# CTRL_MMR0 register map
Vendor: Texas Instruments
Registers are 32-bit, access per field, reset 0x0 unless marked. A register's access mark holds for its fields unless they carry their own. Offsets are as the file gives them; [hi:lo] are bit positions; {n}, {i} and the like mark numbered series; 'fields as' and 'values as' point back to an identical list.

## CTRL_MMR0 (part 2 of 2)
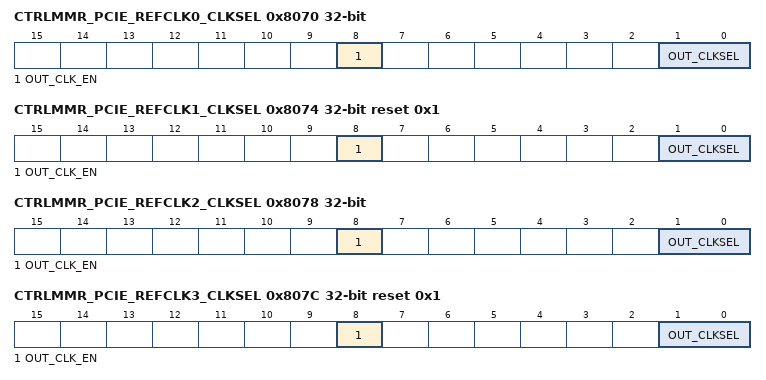
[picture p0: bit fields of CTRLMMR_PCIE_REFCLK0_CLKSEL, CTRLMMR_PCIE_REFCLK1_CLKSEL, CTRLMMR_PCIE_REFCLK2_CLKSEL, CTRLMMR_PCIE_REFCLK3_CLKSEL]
0x8070 CTRLMMR_PCIE_REFCLK0_CLKSEL — Selects the ACSPCIE clock source for the PCIE_REFCLK0 P/N output pins PCIE_REFCLK[1:0] P/N are driven by ACSPCIE0 PAD[1:0] and PCIE_REFCLK[3:2] P/N are driven by ACSPCIE1 PAD[1:0].
  [8] OUT_CLK_EN rw — Enables the output of the ACSPCIE buffer to drive the PCIE0 REFCLK P/N pins
  [1:0] OUT_CLKSEL rw — Selects the PCIE0 REFCLK output clock source. 0h - SERDES0_REF_DER_OUT_CLK 1h - SERDES1_REF_DER_OUT_CLK 2h - SERDES0_REFCLK1_OUT 3h - SERDES1_REFCLK1_OUT
0x8074 CTRLMMR_PCIE_REFCLK1_CLKSEL reset 0x1 — Selects the ACSPCIE clock source for the PCIE_REFCLK1 P/N output pins PCIE_REFCLK[1:0] P/N are driven by ACSPCIE0 PAD[1:0] and PCIE_REFCLK[3:2] P/N are driven by ACSPCIE1 PAD[1:0].
  [8] OUT_CLK_EN rw — Enables the output of the ACSPCIE buffer to drive the PCIE1 REFCLK P/N pins
  [1:0] OUT_CLKSEL rw — Selects the PCIE1 REFCLK output clock source. 0h - SERDES0_REF_DER_OUT_CLK 1h - SERDES1_REF_DER_OUT_CLK 2h - SERDES0_REFCLK1_OUT 3h - SERDES1_REFCLK1_OUT
0x8078 CTRLMMR_PCIE_REFCLK2_CLKSEL — Selects the ACSPCIE clock source for the PCIE_REFCLK2 P/N output pins PCIE_REFCLK[1:0] P/N are driven by ACSPCIE0 PAD[1:0] and PCIE_REFCLK[3:2] P/N are driven by ACSPCIE1 PAD[1:0].
  [8] OUT_CLK_EN rw — Enables the output of the ACSPCIE buffer to drive the PCIE2 REFCLK P/N pins
  [1:0] OUT_CLKSEL rw — Selects the PCIE2 REFCLK output clock source. 0h - SERDES2_REF_DER_OUT_CLK 1h - SERDES3_REF_DER_OUT_CLK 2h - SERDES2_REFCLK1_OUT 3h - SERDES3_REFCLK1_OUT
0x807C CTRLMMR_PCIE_REFCLK3_CLKSEL reset 0x1 — Selects the ACSPCIE clock source for the PCIE_REFCLK3 P/N output pins PCIE_REFCLK[1:0] P/N are driven by ACSPCIE0 PAD[1:0] and PCIE_REFCLK[3:2] P/N are driven by ACSPCIE1 PAD[1:0].
  [8] OUT_CLK_EN rw — Enables the output of the ACSPCIE buffer to drive the PCIE3 REFCLK P/N pins
  [1:0] OUT_CLKSEL rw — Selects the PCIE3 REFCLK output clock source. 0h - SERDES2_REF_DER_OUT_CLK 1h - SERDES3_REF_DER_OUT_CLK 2h - SERDES2_REFCLK1_OUT 3h - SERDES3_REFCLK1_OUT
{0x8080+4i} CTRLMMR_PCIE{i}_CLKSEL (i=0..3) — Selects PCIe{i} functional clock sources.
  [3:0] CPTS_CLKSEL rw — Selects the clock source for the PCIE{i} Common Platform Time Stamp module 0h - MAIN_PLL3_HSDIV1_CLKOUT 1h - MAIN_PLL0_HSDIV6_CLKOUT 2h - MCU_CPTS_REF_CLK (pin) 3h - CPTS_RFT_CLK (pin) 4h - MCU_EXT_REFCLK0 (pin) 5h - EXT_REFCLK1 (pin) 6h - SERDES0_IP2_LN0_TXMCLK 7h - SERDES0_IP2_LN1_TXMCLK 8h - SERDES1_IP2_LN0_TXMCLK 9h - SERDES1_IP2_LN1_TXMCLK Ah - SERDES2_IP2_LN0_TXMCLK Bh - SERDES2_IP2_LN1_TXMCLK Ch - SERDES3_IP2_LN0_TXMCLK Dh - SERDES3_IP2_LN1_TXMCLK Eh - MCU_PLL2_HSDIV1_CLKOUT Fh - MAIN_SYSCLK0
0x8090 CTRLMMR_CPSW_CLKSEL — Selects the 9X CP Switch clock sources.
  [3:0] CPTS_CLKSEL rw — Selects the clock source for the CPSW9x Ethernet switch Common Platform Time Stamp module 0h - MAIN_PLL3_HSDIV1_CLKOUT 1h - MAIN_PLL0_HSDIV6_CLKOUT 2h - MCU_CPTS_REF_CLK (pin) 3h - CPTS_RFT_CLK (pin) 4h - MCU_EXT_REFCLK0 (pin) 5h - EXT_REFCLK1 (pin) 6h - SERDES0_IP2_LN0_TXMCLK 7h - SERDES0_IP2_LN1_TXMCLK 8h - SERDES1_IP2_LN0_TXMCLK 9h - SERDES1_IP2_LN1_TXMCLK Ah - SERDES2_IP2_LN0_TXMCLK Bh - SERDES2_IP2_LN1_TXMCLK Ch - SERDES3_IP2_LN0_TXMCLK Dh - SERDES3_IP2_LN1_TXMCLK Eh - MCU_PLL2_HSDIV1_CLKOUT Fh - MAIN_SYSCLK0
0x8098 CTRLMMR_NAVSS_CLKSEL — Selects the clock source for the Nav Subsystem.
  [3:0] CPTS_CLKSEL rw — Selects the clock source for the SoC] Common Platform Time Stamp module located within the Nav Subsystem 0h - MAIN_PLL3_HSDIV1_CLKOUT 1h - MAIN_PLL0_HSDIV6_CLKOUT 2h - MCU_CPTS_REF_CLK (pin) 3h - CPTS_RFT_CLK (pin) 4h - MCU_EXT_REFCLK0 (pin) 5h - EXT_REFCLK1 (pin) 6h - SERDES0_IP2_LN0_TXMCLK 7h - SERDES0_IP2_LN1_TXMCLK 8h - SERDES1_IP2_LN0_TXMCLK 9h - SERDES1_IP2_LN1_TXMCLK Ah - SERDES2_IP2_LN0_TXMCLK Bh - SERDES2_IP2_LN1_TXMCLK Ch - SERDES3_IP2_LN0_TXMCLK Dh - SERDES3_IP2_LN1_TXMCLK Eh - MCU_PLL2_HSDIV1_CLKOUT Fh - MAIN_SYSCLK0
0x80B0 CTRLMMR_EMMC0_CLKSEL — Selects the functional clock source for 8-bit eMMC0.
  [1:0] CLK_SEL rw — eMMC XIN_CLK selection
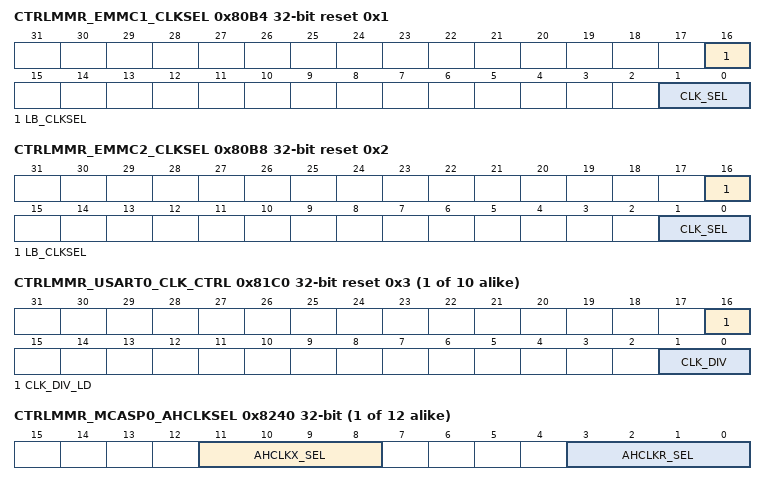
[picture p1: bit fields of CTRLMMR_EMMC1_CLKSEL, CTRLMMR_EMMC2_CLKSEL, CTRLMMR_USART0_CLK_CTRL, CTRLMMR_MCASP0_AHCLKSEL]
0x80B4 CTRLMMR_EMMC1_CLKSEL reset 0x1 — Selects the functional clock source for 4-bit eMMC1.
  [16] LB_CLKSEL rw — eMMC Loopback clock selection
  [1:0] CLK_SEL rw — eMMC XIN_CLK selection
0x80B8 CTRLMMR_EMMC2_CLKSEL reset 0x2 — Selects the functional clock source for 4-bit eMMC2.
  fields as CTRLMMR_EMMC1_CLKSEL
0x80C0 CTRLMMR_UFS0_CLKSEL — Selects the clocks for Universal Flash Storage 0 interface.
  [1:0] MCLK_SEL rw — Selects the MPHY clock source
0x80D0 CTRLMMR_GPMC_CLKSEL — Selects the bus and functional clock source for the GPMC module. This allows the GPMC to run asynchronously to the bus fabric in order to optimize parallel port performance.
  [1:0] CLK_SEL rw — Selects the GPMC clock source
0x80E0 CTRLMMR_USB0_CLKSEL — Selects the functional clock sources for USB0.
  [0] REFCLK_SEL rw — Selects the clock source for the USB0 ref_clk.
0x80E4 CTRLMMR_USB1_CLKSEL — Selects the functional clock sources for USB1.
  [0] REFCLK_SEL rw — Selects the clock source for the USB1 ref_clk.
{0x8100+4i} CTRLMMR_TIMER{i}_CLKSEL (i=0..19) — Timer{i} functional clock selection control.
  [3:0] CLK_SEL rw — Timer functional clock input select mux control 0h - WKUP_HFOSC0_CLKOUT 1h - HFOSC1_CLKOUT 2h - MAIN_PLL0_HSDIV1_CLKOUT 3h - CLK_12M_RC 4h - MAIN_PLL3_HSDIV3_CLKOUT 5h - MCU_EXT_REFCLK0 (pin) 6h - EXT_REFCLK1 (pin) 7h - LPXOSC_CLKOUT 8h - CPTS_RFT_CLK (pin) 9h - MAIN_PLL1_HSDIV3_CLKOUT Ah - MAIN_PLL2_HSDIV6_CLKOUT Bh - MAIN_PLL4_HSDIV2_CLKOUT Ch - CPTS_GENF2 Dh - CPTS_GENF3 Eh - CPSW9G_CPTS_GENF0 Fh - MAIN_PLL15_HSDIV2_CLKOUT
{0x8190+4i} CTRLMMR_SPI{i}_CLKSEL (i=0..3) — SPI{i} clock control.
  [16] MSTR_LB_CLKSEL rw — Master mode receive capture clock loopback selection
{0x8190+4i} CTRLMMR_SPI{i}_CLKSEL (i=5..7) — SPI{i} clock control.
  fields as CTRLMMR_SPI0_CLKSEL
{0x81C0+4i} CTRLMMR_USART{i}_CLK_CTRL reset 0x3 (i=0..9) — Selects the clock divider of the USART{i} functional clock.
  [16] CLK_DIV_LD rw — Load the output divider value
  [1:0] CLK_DIV rw — Selects the clock divider value. Supports divide values of 1 to 4 Default is /4. To load the new divider value the clk_div_ld bit must be cleared and then set to 1. 0h - Divide by 1 1h - Divide by 2 2h - Divide by 3 3h - Divide by 4
{0x8200+4i} CTRLMMR_MCASP{i}_CLKSEL (i=0..11) — Selects the functional clock source for McASP{i}.
  [2:0] AUXCLK_SEL rw — Selects the McASP{i} auxclk clock source 0h - MAIN_PLL4_HSDIV0_CLKOUT 1h - MAIN_PLL2_HSDIV2_CLKOUT 2h - MAIN_PLL15_HSDIV0_CLKOUT 3h - '0' 4h - ATCLK0 5h - ATCLK1 6h - ATCLK2 7h - ATCLK3
{0x8240+4i} CTRLMMR_MCASP{i}_AHCLKSEL (i=0..11) — Selects the AHCLKX and AHCLKR clock source for McASP{i}.
  [11:8] AHCLKX_SEL rw — Selects the AHCLKX input source for McASP{i}. Not shown values are reserved. 0h - HFOSC1_CLKOUT 1h - WKUP_HFOSC0_CLKOUT 2h - AUDIO_EXT_REFCLK0_IN 3h - AUDIO_EXT_REFCLK1_IN 4h - AUDIO_EXT_REFCLK2_IN 5h - AUDIO_EXT_REFCLK3_IN 6h - MLB_IO_CLK 7h - MLBP_IO_CLK / 2 8h - ATCLK0 9h - ATCLK1 Ah - ATCLK2 Bh - ATCLK3
  [3:0] AHCLKR_SEL rw — Selects the AHCLKR input source for McASP{i} 0h - HFOSC1_CLKOUT 1h - WKUP_HFOSC0_CLKOUT 2h - AUDIO_EXT_REFCLK0_IN 3h - AUDIO_EXT_REFCLK1_IN 4h - AUDIO_EXT_REFCLK2_IN 5h - AUDIO_EXT_REFCLK3_IN 6h - MLB_IO_CLK 7h - MLBP_IO_CLK / 2 8h - ATCLK0 9h - ATCLK1 Ah - ATCLK2 Bh - ATCLK3 Ch - '0' Dh - '0' Eh - '0' Fh - '0'
{0x8280+4i} CTRLMMR_ASRC_RXSYNC{i}_SEL (i=0..3) — Selects the source signal for the ASRC RXSYNC{i} frame sync input.
  [5:0] SYNC_SEL rw — RXSYNC source signal. Not shown values are reserved. 0h - McASP0 AFSR Pin Input 1h - McASP1 AFSR Pin Input 2h - McASP2 AFSR Pin Input 3h - McASP3 AFSR Pin Input 4h - McASP4 AFSR Pin Input 5h - McASP5 AFSR Pin Input 6h - McASP6 AFSR Pin Input 7h - McASP7 AFSR Pin Input 8h - McASP8 AFSR Pin Input 9h - McASP9 AFSR Pin Input Ah - McASP10 AFSR Pin Input Bh - McASP11 AFSR Pin Input Ch - McASP0 AFSX Pin Input Dh - McASP1 AFSX Pin Input Eh - McASP2 AFSX Pin Input Fh - McASP3 AFSX Pin Input 10h - McASP4 AFSX Pin Input 11h - McASP5 AFSX Pin Input 12h - McASP6 AFSX Pin Input 13h - McASP7 AFSX Pin Input 14h - McASP8 AFSX Pin Input 15h - McASP9 AFSX Pin Input 16h - McASP10 AFSX Pin Input 17h - McASP11 AFSX Pin Input 18h - AUDIO_EXT_REFCLK0 Pin input 19h - AUDIO_EXT_REFCLK1 Pin input 1Ah - AUDIO_EXT_REFCLK2 Pin input 1Bh - AUDIO_EXT_REFCLK3 Pin input 1Ch - MLB_IO_CLK 1Dh - MLBP_IO_CLK /2 1Eh - MAIN_PLL4_HSDIV3_CLKOUT 1Fh - MAIN_PLL15_HSDIV3_CLKOUT 20h - ADC0_CLK 21h - ADC1_CLK 22h - MCU_EXT_REFCLK0 Pin 23h - EXT_REFCLK1 Pin
{0x8290+4i} CTRLMMR_ASRC_TXSYNC{i}_SEL (i=0..3) — Selects the source signal for the ASRC TXSYNC{i} frame sync input.
  [5:0] SYNC_SEL rw — TXSYNC source signal. Not shown values are reserved. 0h - McASP0 AFSX Pin Input 1h - McASP1 AFSX Pin Input 2h - McASP2 AFSX Pin Input 3h - McASP3 AFSX Pin Input 4h - McASP4 AFSX Pin Input 5h - McASP5 AFSX Pin Input 6h - McASP6 AFSX Pin Input 7h - McASP7 AFSX Pin Input 8h - McASP8 AFSX Pin Input 9h - McASP9 AFSX Pin Input Ah - McASP10 AFSX Pin Input Bh - McASP11 AFSX Pin Input Ch - McASP0 AFSX Pin Input Dh - McASP1 AFSX Pin Input Eh - McASP2 AFSX Pin Input Fh - McASP3 AFSX Pin Input 10h - McASP4 AFSX Pin Input 11h - McASP5 AFSX Pin Input 12h - McASP6 AFSX Pin Input 13h - McASP7 AFSX Pin Input 14h - McASP8 AFSX Pin Input 15h - McASP9 AFSX Pin Input 16h - McASP10 AFSX Pin Input 17h - McASP11 AFSX Pin Input 18h - AUDIO_EXT_REFCLK0 Pin input 19h - AUDIO_EXT_REFCLK1 Pin input 1Ah - AUDIO_EXT_REFCLK2 Pin input 1Bh - AUDIO_EXT_REFCLK3 Pin input 1Ch - MLB_IO_CLK 1Dh - MLBP_IO_CLK /2 1Eh - MAIN_PLL4_HSDIV3_CLKOUT 1Fh - MAIN_PLL15_HSDIV3_CLKOUT 20h - ADC0_CLK 21h - ADC1_CLK 22h - MCU_EXT_REFCLK0 Pin 23h - EXT_REFCLK1 Pin
{0x82A0+4i} CTRLMMR_ATL_BWS{i}_SEL (i=0..3) — Selects the source of ATL Baseband Word Select {i}.
  [4:0] WD_SEL rw — BWS source signal. Not shown values are reserved. 0h - McASP0 AFSR Pin Input 1h - McASP1 AFSR Pin Input 2h - McASP2 AFSR Pin Input 3h - McASP3 AFSR Pin Input 4h - McASP4 AFSR Pin Input 5h - McASP5 AFSR Pin Input 6h - McASP6 AFSR Pin Input 7h - McASP7 AFSR Pin Input 8h - McASP8 AFSR Pin Input 9h - McASP9 AFSR Pin Input Ah - McASP10 AFSR Pin Input Bh - McASP11 AFSR Pin Input Ch - McASP0 AFSX Pin Input Dh - McASP1 AFSX Pin Input Eh - McASP2 AFSX Pin Input Fh - McASP3 AFSX Pin Input 10h - McASP4 AFSX Pin Input 11h - McASP5 AFSX Pin Input 12h - McASP6 AFSX Pin Input 13h - McASP7 AFSX Pin Input 14h - McASP8 AFSX Pin Input 15h - McASP9 AFSX Pin Input 16h - McASP10 AFSX Pin Input 17h - McASP11 AFSX Pin Input 18h - AUDIO_EXT_REFCLK0 Pin input 19h - AUDIO_EXT_REFCLK1 Pin input 1Ah - AUDIO_EXT_REFCLK2 Pin input 1Bh - AUDIO_EXT_REFCLK3 Pin input
{0x82B0+4i} CTRLMMR_ATL_AWS{i}_SEL (i=0..3) — Selects the source of ATL Audio Word Select {i}.
  [4:0] WD_SEL rw — AWS source signal. Not shown values are reserved. 0h - McASP0 AFSX Pin Input 1h - McASP1 AFSX Pin Input 2h - McASP2 AFSX Pin Input 3h - McASP3 AFSX Pin Input 4h - McASP4 AFSX Pin Input 5h - McASP5 AFSX Pin Input 6h - McASP6 AFSX Pin Input 7h - McASP7 AFSX Pin Input 8h - McASP8 AFSX Pin Input 9h - McASP9 AFSX Pin Input Ah - McASP10 AFSX Pin Input Bh - McASP11 AFSX Pin Input Ch - McASP0 AFSX Pin Input Dh - McASP1 AFSX Pin Input Eh - McASP2 AFSX Pin Input Fh - McASP3 AFSX Pin Input 10h - McASP4 AFSX Pin Input 11h - McASP5 AFSX Pin Input 12h - McASP6 AFSX Pin Input 13h - McASP7 AFSX Pin Input 14h - McASP8 AFSX Pin Input 15h - McASP9 AFSX Pin Input 16h - McASP10 AFSX Pin Input 17h - McASP11 AFSX Pin Input 18h - AUDIO_EXT_REFCLK0 Pin input 19h - AUDIO_EXT_REFCLK1 Pin input 1Ah - AUDIO_EXT_REFCLK2 Pin input 1Bh - AUDIO_EXT_REFCLK3 Pin input 1Ch - MLB_IO_CLK 1Dh - MLBP_IO_CLK /2
0x82C0 CTRLMMR_ATL_CLKSEL — Selects the source of the ATL PCLK.
  [3:0] PCLK_SEL rw — Selects the PCLK clock source 0h - MAIN_PLL4_HSDIV1_CLKOUT 1h - MAIN_PLL2_HSDIV2_CLKOUT 2h - MAIN_PLL15_HSDIV1_CLKOUT 3h - '0' 4h - MAIN_PLL0_HSDIV7_CLKOUT 5h - MCU_EXT_REFCLK0 (pin) 6h - EXT_REFCLK1 (pin) 7h - '0'
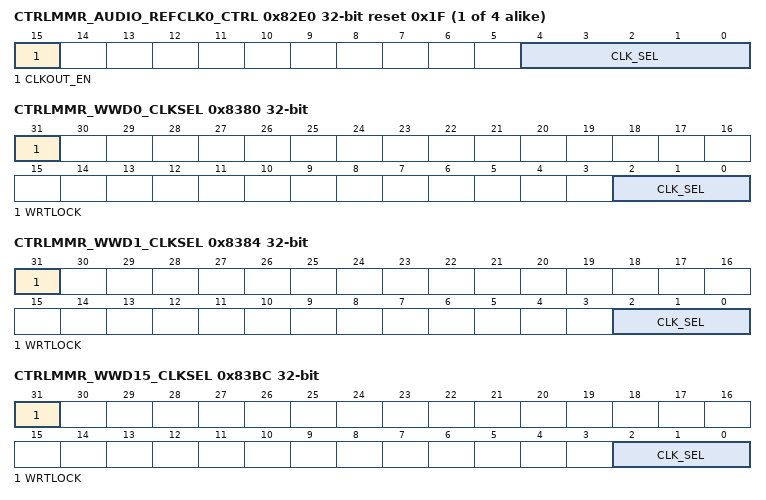
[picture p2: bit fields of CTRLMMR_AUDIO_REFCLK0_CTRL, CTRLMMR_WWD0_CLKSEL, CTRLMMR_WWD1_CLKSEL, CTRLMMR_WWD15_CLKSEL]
{0x82E0+4i} CTRLMMR_AUDIO_REFCLK{i}_CTRL reset 0x1F (i=0..3) — Selects the clock source for the AUDIO_EXT_REFCLK{i} output.
  [15] CLKOUT_EN rw — AUDIO_REFCLK {i} output enable
  [4:0] CLK_SEL rw — Clock source 0h - MCASP0 AHCLKR Output 1h - MCASP1 AHCLKR Output 2h - MCASP2 AHCLKR Output 3h - MCASP3 AHCLKR Output 4h - MCASP4 AHCLKR Output 5h - MCASP5 AHCLKR Output 6h - MCASP6 AHCLKR Output 7h - MCASP7 AHCLKR Output 8h - MCASP8 AHCLKR Output 9h - MCASP9 AHCLKR Output Ah - MCASP10 AHCLKR Output Bh - MCASP11 AHCLKR Output Ch - MCASP0 AHCLKX Output Dh - MCASP1 AHCLKX Output Eh - MCASP2 AHCLKX Output Fh - MCASP3 AHCLKX Output 10h - MCASP4 AHCLKX Output 11h - MCASP5 AHCLKX Output 12h - MCASP6 AHCLKX Output 13h - MCASP7 AHCLKX Output 14h - MCASP8 AHCLKX Output 15h - MCASP9 AHCLKX Output 16h - MCASP10 AHCLKX Output 17h - MCASP11 AHCLKX Output 18h - ATCLK0 19h - ATCLK1 1Ah - ATCLK2 1Bh - ATCLK3 1Ch - MAIN_PLL4_HSDIV2_CLKOUT 1Dh - MAIN_PLL15_HSDIV2_CLKOUT 1Eh - '0' 1Fh - '0'
0x8300 CTRLMMR_DPI0_CLK_CTRL — Selects the clock source for the DPI0 video output.
  [0] EXT_CLKSEL rw — Selects whether to use DSS PLL3 or an external pin as a DPI clock source.
0x8304 CTRLMMR_DPI1_CLK_CTRL — Selects the clock source for the DPI1 video output.
  [0] EXT_CLKSEL rw — Selects whether to use DSS PLL7 or an external pin as a DPI clock source.
0x8310 CTRLMMR_DPHY0_CLKSEL — Selects the clock source for the DSI0 transmit PHY.
  [1:0] REF_CLK_SEL rw — DPHY reference clock source
0x8324 CTRLMMR_DSS_DISPC0_CLKSEL1 — Selects the clock source for DPI Lane 1 of Display Controller Instance 0.
  [1:0] DPI1_PCLK rw — DPI lane 1 pixel clock source 0h - MAIN_PLL17_HSDIV0_CLKOUT 1h - MAIN_PLL19_HSDIV0_CLKOUT_EXTPCLKIN 2h - MAIN_PLL23_HSDIV0_CLKOUT_EXTPCLKIN 3h - MAIN_PLL16_HSDIV1_CLKOUT
0x8328 CTRLMMR_DSS_DISPC0_CLKSEL2 — Selects the clock source for DPI Lane 2 of Display Controller Instance 0.
  [0] DPI2_PCLK rw — DPI lane 2 pixel clock source 0h - MAIN_PLL16_HSDIV0_CLKOUT 1h - MAIN_PLL18_HSDIV0_CLKOUT
0x832C CTRLMMR_DSS_DISPC0_CLKSEL3 — Selects the clock source for DPI Lane 3 of Display Controller Instance 0 Can also override the DPI Lane 0 and DPI Lane 2 clock source for certain values.
  [2:0] DPI3_PCLK rw — DPI lane 3 pixel clock source 0h - MAIN_PLL16_HSDIV1_CLKOUT 1h - MAIN_PLL17_HSDIV1_CLKOUT 2h - MAIN_PLL18_HSDIV1_CLKOUT 3h - MAIN_PLL19_HSDIV0_CLKOUT_EXTPCLKIN 4h - MAIN_PLL23_HSDIV0_CLKOUT_EXTPCLKIN 5h - MAIN_PLL23_HSDIV0_CLKOUT_EXTPCLKIN and dpi0_pclk = dpi1_pclk 6h - MAIN_PLL23_HSDIV0_CLKOUT_EXTPCLKIN and dpi2_pclk = MAIN_PLL19_HSDIV0_CLKOUT_EXTPCLKIN 7h - MAIN_PLL23_HSDIV0_CLKOUT_EXTPCLKIN and dpi0_pclk = dpi1_pclk and dpi2_pclk = MAIN_PLL19_HSDIV0_CLKOUT_EXTPCLKIN
0x8340 CTRLMMR_EDP_PHY0_CLKSEL — Selects the Phy core clock for Embedded Display Port Phy0.
  [1:0] CLK_SEL rw — EDP PHY CORE_REFCLK clock source
0x8350 CTRLMMR_EDP0_CLK_CTRL — Controls clock operation for Embedded Display Port 0.
  [8] DSI_CLK_DYN_SWTCH_DIS rw — EDP0 DSI clock dynamic switch disable.
0x8380 CTRLMMR_WWD0_CLKSEL — ARM MPU Core 0 Windowed watchdog timer functional clock selection control.
  [31] WRTLOCK rw — When set, locks
  [2:0] CLK_SEL rw — Windowed watchdog timer functional clock input select mux control 0h - WKUP_HFOSC0_CLKOUT 1h - LPXOSC_CLKOUT 2h - CLK_12M_RC 3h - CLK_32K 4h - HFOSC1_CLKOUT 5h - reserved (HFOSC1_CLKOUT) 6h - reserved (HFOSC1_CLKOUT) 7h - reserved (HFOSC1_CLKOUT)
0x8384 CTRLMMR_WWD1_CLKSEL — ARM MPU Core 1 Windowed watchdog timer functional clock selection control.
  fields as CTRLMMR_WWD0_CLKSEL
0x83BC CTRLMMR_WWD15_CLKSEL — GPU Windowed watchdog timer functional clock selection control.
  fields as CTRLMMR_WWD0_CLKSEL
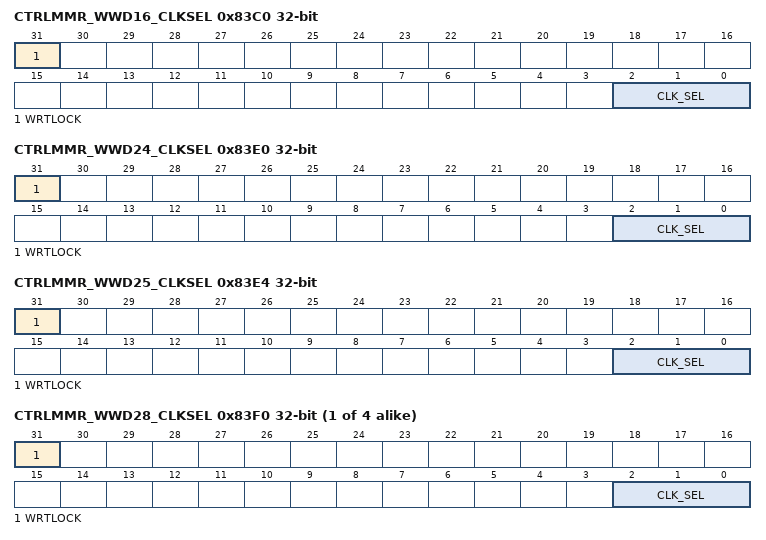
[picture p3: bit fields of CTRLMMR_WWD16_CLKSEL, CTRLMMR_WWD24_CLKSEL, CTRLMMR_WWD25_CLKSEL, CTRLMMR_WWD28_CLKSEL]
0x83C0 CTRLMMR_WWD16_CLKSEL — C71x Core 0 Windowed watchdog timer functional clock selection control.
  fields as CTRLMMR_WWD0_CLKSEL
0x83E0 CTRLMMR_WWD24_CLKSEL — C66x Core 0 Windowed watchdog timer functional clock selection control.
  fields as CTRLMMR_WWD0_CLKSEL
0x83E4 CTRLMMR_WWD25_CLKSEL — C66x Core 1 Windowed watchdog timer functional clock selection control.
  fields as CTRLMMR_WWD0_CLKSEL
{0x8380+4i} CTRLMMR_WWD{i}_CLKSEL (i=28..31) — Main R5 Core {i-28} Windowed watchdog timer functional clock selection control.
  fields as CTRLMMR_WWD0_CLKSEL
{0x8400+0x10*i} CTRLMMR_SERDES{i}_CLKSEL (i=0..3) — Selects the clock source for Lane 0 when configured as 2 single lane PHYs and Lane 0-1 when configured as a dual lane PHY.
  [1:0] CORE_REFCLK_SEL rw — Selects the source for the core_refclk input 0h - WKUP_HFOSC0_CLKOUT 1h - HFOSC1_CLKOUT 2h - MAIN_PLL3_HSDIV4_CLKOUT 3h - MAIN_PLL2_HSDIV4_CLKOUT
{0x8404+0x10*i} CTRLMMR_SERDES{i}_CLK1SEL (i=0..3) — Selects the clock source for Lane1 when configured as 2 single lane PHYs.
  [1:0] CORE_REFCLK1_SEL rw — Selects the source for the core_refclk1 input 0h - WKUP_HFOSC0_CLKOUT 1h - HFOSC1_CLKOUT 2h - MAIN_PLL3_HSDIV4_CLKOUT 3h - MAIN_PLL2_HSDIV4_CLKOUT
{0x8480+4i} CTRLMMR_MCAN{i}_CLKSEL (i=0..13) — Controls the functional clock source MCAN{i}.
  [1:0] CLK_SEL rw — MAIN MCAN_CLK selection
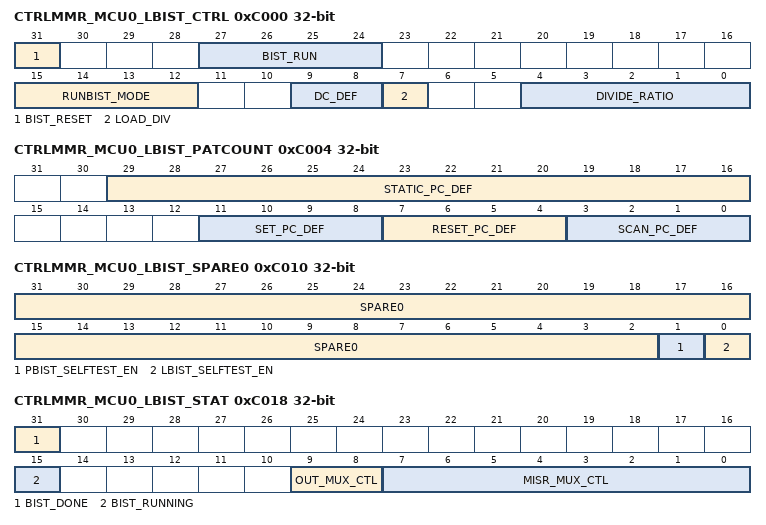
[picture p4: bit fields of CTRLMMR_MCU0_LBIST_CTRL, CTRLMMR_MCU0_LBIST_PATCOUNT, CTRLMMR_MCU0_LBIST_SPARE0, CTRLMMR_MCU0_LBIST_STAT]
0xC000 CTRLMMR_MCU0_LBIST_CTRL — Configures and enables LBIST operation.
  [31] BIST_RESET rw — Reset LBIST macro
  [27:24] BIST_RUN rw — Starts LBIST if all bits are 1
  [15:12] RUNBIST_MODE rw — Runbist mode enable if all bits are 1
  [9:8] DC_DEF rw — Clock delay after scan_enable switching
  [7] LOAD_DIV rw — Loads LBIST clock divide ratio on transition from 0 to 1
  [4:0] DIVIDE_RATIO rw — LBIST clock divide ratio
0xC004 CTRLMMR_MCU0_LBIST_PATCOUNT — Specifies the number of LBIST patterns to run.
  [29:16] STATIC_PC_DEF rw — Number of stuck-at patterns to run
  [11:8] SET_PC_DEF rw — Number of set patterns to run
  [7:4] RESET_PC_DEF rw — Number of reset patterns to run
  [3:0] SCAN_PC_DEF rw — Number of chain test patterns to run
0xC008 CTRLMMR_MCU0_LBIST_SEED0 rw — Specifies the 32 LSBs of the PRPG seed.
  [31:0] PRPG_DEF — Initial seed for PRPG (bits 31:0)
0xC00C CTRLMMR_MCU0_LBIST_SEED1 — Specifies the 21 MSBs of the PRPG seed.
  [20:0] PRPG_DEF rw — Initial seed for PRPG (bits 52:32)
0xC010 CTRLMMR_MCU0_LBIST_SPARE0 rw — Spare LBIST control bits.
  [31:2] SPARE0 — LBIST spare bits
  [1] PBIST_SELFTEST_EN — PBIST isolation control
  [0] LBIST_SELFTEST_EN — LBIST isolation control
0xC014 CTRLMMR_MCU0_LBIST_SPARE1 rw — Spare LBIST control bits.
  [31:0] SPARE1 — LBIST spare bits
0xC018 CTRLMMR_MCU0_LBIST_STAT (reset mask 0x7FFF7FFF) — Indicates LBIST status and provides MISR selection control.
  [31] BIST_DONE ro — LBIST is done
  [15] BIST_RUNNING ro — LBIST is running
  [9:8] OUT_MUX_CTL rw — Selects source of LBIST output
  [7:0] MISR_MUX_CTL rw — Selects block of 32 MISR bits to read. A value of 0 selects a compacted 32-bit version of the full MISR. A value of 1-32 select a 32-bit segment of the MISR.
0xC01C CTRLMMR_MCU0_LBIST_MISR ro reset not defined — Contains LBIST MISR output value.
  [31:0] MISR_RESULT — 32-bits of MISR value selected by misr_mux_ctl
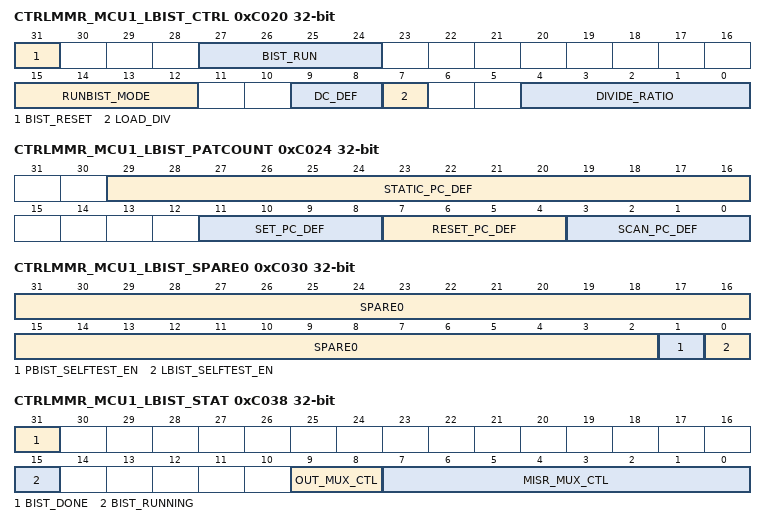
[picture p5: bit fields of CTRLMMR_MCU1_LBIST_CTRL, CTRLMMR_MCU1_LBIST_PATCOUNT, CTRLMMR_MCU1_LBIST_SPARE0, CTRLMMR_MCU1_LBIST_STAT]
0xC020 CTRLMMR_MCU1_LBIST_CTRL — Configures and enables LBIST operation.
  fields as CTRLMMR_MCU0_LBIST_CTRL
0xC024 CTRLMMR_MCU1_LBIST_PATCOUNT — Specifies the number of LBIST patterns to run.
  fields as CTRLMMR_MCU0_LBIST_PATCOUNT
0xC028 CTRLMMR_MCU1_LBIST_SEED0 rw — Specifies the 32 LSBs of the PRPG seed.
  [31:0] PRPG_DEF — Initial seed for PRPG (bits 31:0)
0xC02C CTRLMMR_MCU1_LBIST_SEED1 — Specifies the 21 MSBs of the PRPG seed.
  [20:0] PRPG_DEF rw — Initial seed for PRPG (bits 52:32)
0xC030 CTRLMMR_MCU1_LBIST_SPARE0 rw — Spare LBIST control bits.
  fields as CTRLMMR_MCU0_LBIST_SPARE0
0xC034 CTRLMMR_MCU1_LBIST_SPARE1 rw — Spare LBIST control bits.
  [31:0] SPARE1 — LBIST spare bits
0xC038 CTRLMMR_MCU1_LBIST_STAT (reset mask 0x7FFF7FFF) — Indicates LBIST status and provides MISR selection control.
  fields as CTRLMMR_MCU0_LBIST_STAT
0xC03C CTRLMMR_MCU1_LBIST_MISR ro reset not defined — Contains LBIST MISR output value.
  [31:0] MISR_RESULT — 32-bits of MISR value selected by misr_mux_ctl
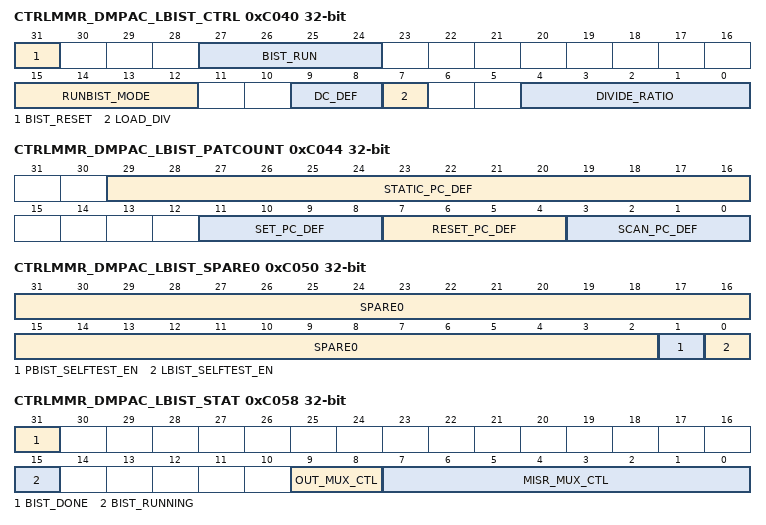
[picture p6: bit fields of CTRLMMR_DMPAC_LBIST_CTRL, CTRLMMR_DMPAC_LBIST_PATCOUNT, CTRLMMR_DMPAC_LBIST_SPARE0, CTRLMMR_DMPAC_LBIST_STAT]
0xC040 CTRLMMR_DMPAC_LBIST_CTRL — Configures and enables LBIST operation.
  fields as CTRLMMR_MCU0_LBIST_CTRL
0xC044 CTRLMMR_DMPAC_LBIST_PATCOUNT — Specifies the number of LBIST patterns to run.
  fields as CTRLMMR_MCU0_LBIST_PATCOUNT
0xC048 CTRLMMR_DMPAC_LBIST_SEED0 rw — Specifies the 32 LSBs of the PRPG seed.
  [31:0] PRPG_DEF — Initial seed for PRPG (bits 31:0)
0xC04C CTRLMMR_DMPAC_LBIST_SEED1 — Specifies the 21 MSBs of the PRPG seed.
  [20:0] PRPG_DEF rw — Initial seed for PRPG (bits 52:32)
0xC050 CTRLMMR_DMPAC_LBIST_SPARE0 rw — Spare LBIST control bits.
  fields as CTRLMMR_MCU0_LBIST_SPARE0
0xC054 CTRLMMR_DMPAC_LBIST_SPARE1 rw — Spare LBIST control bits.
  [31:0] SPARE1 — LBIST spare bits
0xC058 CTRLMMR_DMPAC_LBIST_STAT (reset mask 0x7FFF7FFF) — Indicates LBIST status and provides MISR selection control.
  fields as CTRLMMR_MCU0_LBIST_STAT
0xC05C CTRLMMR_DMPAC_LBIST_MISR ro reset not defined — Contains LBIST MISR output value.
  [31:0] MISR_RESULT — 32-bits of MISR value selected by misr_mux_ctl
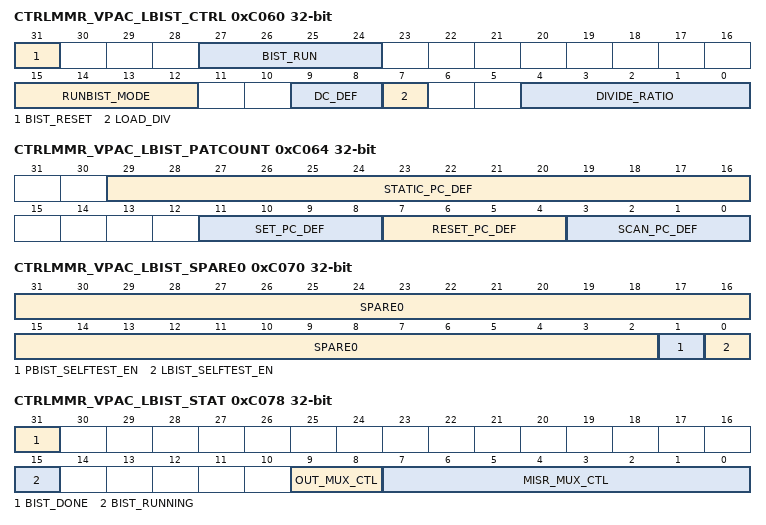
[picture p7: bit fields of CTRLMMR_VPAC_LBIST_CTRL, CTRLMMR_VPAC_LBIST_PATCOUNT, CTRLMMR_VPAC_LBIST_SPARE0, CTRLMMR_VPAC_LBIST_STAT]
0xC060 CTRLMMR_VPAC_LBIST_CTRL — Configures and enables LBIST operation.
  fields as CTRLMMR_MCU0_LBIST_CTRL
0xC064 CTRLMMR_VPAC_LBIST_PATCOUNT — Specifies the number of LBIST patterns to run.
  fields as CTRLMMR_MCU0_LBIST_PATCOUNT
0xC068 CTRLMMR_VPAC_LBIST_SEED0 rw — Specifies the 32 LSBs of the PRPG seed.
  [31:0] PRPG_DEF — Initial seed for PRPG (bits 31:0)
0xC06C CTRLMMR_VPAC_LBIST_SEED1 — Specifies the 21 MSBs of the PRPG seed.
  [20:0] PRPG_DEF rw — Initial seed for PRPG (bits 52:32)
0xC070 CTRLMMR_VPAC_LBIST_SPARE0 rw — Spare LBIST control bits.
  fields as CTRLMMR_MCU0_LBIST_SPARE0
0xC074 CTRLMMR_VPAC_LBIST_SPARE1 rw — Spare LBIST control bits.
  [31:0] SPARE1 — LBIST spare bits
0xC078 CTRLMMR_VPAC_LBIST_STAT (reset mask 0x7FFF7FFF) — Indicates LBIST status and provides MISR selection control.
  fields as CTRLMMR_MCU0_LBIST_STAT
0xC07C CTRLMMR_VPAC_LBIST_MISR ro reset not defined — Contains LBIST MISR output value.
  [31:0] MISR_RESULT — 32-bits of MISR value selected by misr_mux_ctl
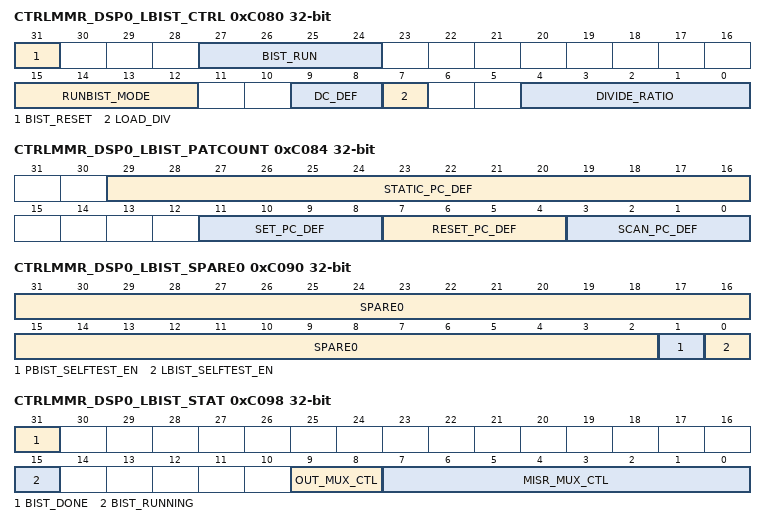
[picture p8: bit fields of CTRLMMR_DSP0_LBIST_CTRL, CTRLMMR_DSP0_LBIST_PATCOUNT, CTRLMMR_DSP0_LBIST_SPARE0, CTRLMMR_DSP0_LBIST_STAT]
0xC080 CTRLMMR_DSP0_LBIST_CTRL — Configures and enables LBIST operation.
  fields as CTRLMMR_MCU0_LBIST_CTRL
0xC084 CTRLMMR_DSP0_LBIST_PATCOUNT — Specifies the number of LBIST patterns to run.
  fields as CTRLMMR_MCU0_LBIST_PATCOUNT
0xC088 CTRLMMR_DSP0_LBIST_SEED0 rw — Specifies the 32 LSBs of the PRPG seed.
  [31:0] PRPG_DEF — Initial seed for PRPG (bits 31:0)
0xC08C CTRLMMR_DSP0_LBIST_SEED1 — Specifies the 21 MSBs of the PRPG seed.
  [20:0] PRPG_DEF rw — Initial seed for PRPG (bits 52:32)
0xC090 CTRLMMR_DSP0_LBIST_SPARE0 rw — Spare LBIST control bits.
  fields as CTRLMMR_MCU0_LBIST_SPARE0
0xC094 CTRLMMR_DSP0_LBIST_SPARE1 rw — Spare LBIST control bits.
  [31:0] SPARE1 — LBIST spare bits
0xC098 CTRLMMR_DSP0_LBIST_STAT (reset mask 0x7FFF7FFF) — Indicates LBIST status and provides MISR selection control.
  fields as CTRLMMR_MCU0_LBIST_STAT
0xC09C CTRLMMR_DSP0_LBIST_MISR ro reset not defined — Contains LBIST MISR output value.
  [31:0] MISR_RESULT — 32-bits of MISR value selected by misr_mux_ctl
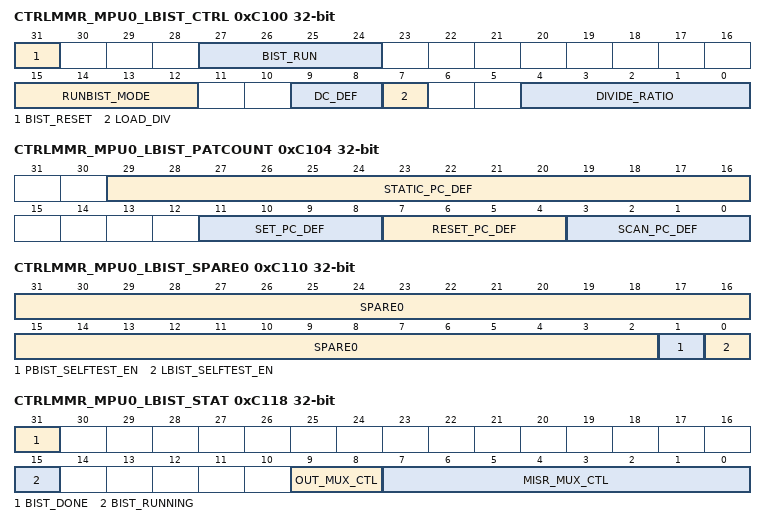
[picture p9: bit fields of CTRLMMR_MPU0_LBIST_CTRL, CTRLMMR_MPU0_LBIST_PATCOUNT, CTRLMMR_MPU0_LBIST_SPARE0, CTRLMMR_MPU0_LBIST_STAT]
0xC100 CTRLMMR_MPU0_LBIST_CTRL — Configures and enables LBIST operation.
  fields as CTRLMMR_MCU0_LBIST_CTRL
0xC104 CTRLMMR_MPU0_LBIST_PATCOUNT — Specifies the number of LBIST patterns to run.
  fields as CTRLMMR_MCU0_LBIST_PATCOUNT
0xC108 CTRLMMR_MPU0_LBIST_SEED0 rw — Specifies the 32 LSBs of the PRPG seed.
  [31:0] PRPG_DEF — Initial seed for PRPG (bits 31:0)
0xC10C CTRLMMR_MPU0_LBIST_SEED1 — Specifies the 21 MSBs of the PRPG seed.
  [20:0] PRPG_DEF rw — Initial seed for PRPG (bits 52:32)
0xC110 CTRLMMR_MPU0_LBIST_SPARE0 rw — Spare LBIST control bits.
  fields as CTRLMMR_MCU0_LBIST_SPARE0
0xC114 CTRLMMR_MPU0_LBIST_SPARE1 rw — Spare LBIST control bits.
  [31:0] SPARE1 — LBIST spare bits
0xC118 CTRLMMR_MPU0_LBIST_STAT (reset mask 0x7FFF7FFF) — Indicates LBIST status and provides MISR selection control.
  fields as CTRLMMR_MCU0_LBIST_STAT
0xC11C CTRLMMR_MPU0_LBIST_MISR ro reset not defined — Contains LBIST MISR output value.
  [31:0] MISR_RESULT — 32-bits of MISR value selected by misr_mux_ctl
0xC280 CTRLMMR_MCU0_LBIST_SIG ro reset not defined — Contains expected MISR output value.
  [31:0] MISR_SIG — MISR signature
0xC284 CTRLMMR_MCU1_LBIST_SIG ro reset not defined — Contains expected MISR output value.
  [31:0] MISR_SIG — MISR signature
0xC288 CTRLMMR_DMPAC_LBIST_SIG ro reset not defined — Contains expected MISR output value.
  [31:0] MISR_SIG — MISR signature
0xC28C CTRLMMR_VPAC_LBIST_SIG ro reset not defined — Contains expected MISR output value.
  [31:0] MISR_SIG — MISR signature
0xC290 CTRLMMR_DSP0_LBIST_SIG ro reset not defined — Contains expected MISR output value.
  [31:0] MISR_SIG — MISR signature
0xC2A0 CTRLMMR_MPU0_LBIST_SIG ro reset not defined — Contains expected MISR output value.
  [31:0] MISR_SIG — MISR signature
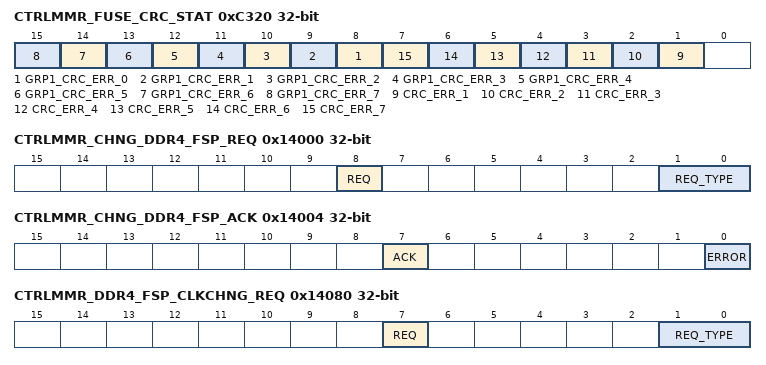
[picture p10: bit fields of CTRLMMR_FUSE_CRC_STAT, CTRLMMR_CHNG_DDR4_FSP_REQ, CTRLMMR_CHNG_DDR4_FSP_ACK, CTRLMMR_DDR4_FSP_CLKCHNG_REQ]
0xC320 CTRLMMR_FUSE_CRC_STAT ro (reset mask 0xFFFF0001) — Indicates status of fuse chain CRC.
  [n+8] GRP1_CRC_ERR_{n} (n=0..7) — Indicates eFuse CRC error on group1 chain {n}
  [n] CRC_ERR_{n} (n=1..7) — Indicates eFuse CRC error on chain {n}
0x14000 CTRLMMR_CHNG_DDR4_FSP_REQ — This register is used to initiate a LPDDR4 frequency set point change to the DDR Controller.
  [8] REQ rw — Initiate FSP frequency change
  [1:0] REQ_TYPE rw — Frequency request type
0x14004 CTRLMMR_CHNG_DDR4_FSP_ACK ro (reset mask 0xFFFFFF7E) — This register is used by the DDR Controller to acknowledge the LPDDR4 frequency set point shange request.
  [7] ACK — Frequency change acknowledge.
  [0] ERROR — Frequency change error
0x14080 CTRLMMR_DDR4_FSP_CLKCHNG_REQ ro (reset mask 0xFFFFFF7C) — This register is used by the DDR Controller to request the DDR PLL clock frequency change. This can occur as part of DDR4 initialization and training or in response to a LPDDR4 FSP change request.
  [7] REQ — DDR Controller FSP clock change request
  [1:0] REQ_TYPE — Frequency request type
0x140C0 CTRLMMR_DDR4_FSP_CLKCHNG_ACK — This register is used to acknowledge a DDR PLL clock frequency change to the DDR Controller.
  [0] ACK rw — DDR FSP clock change ackowledge
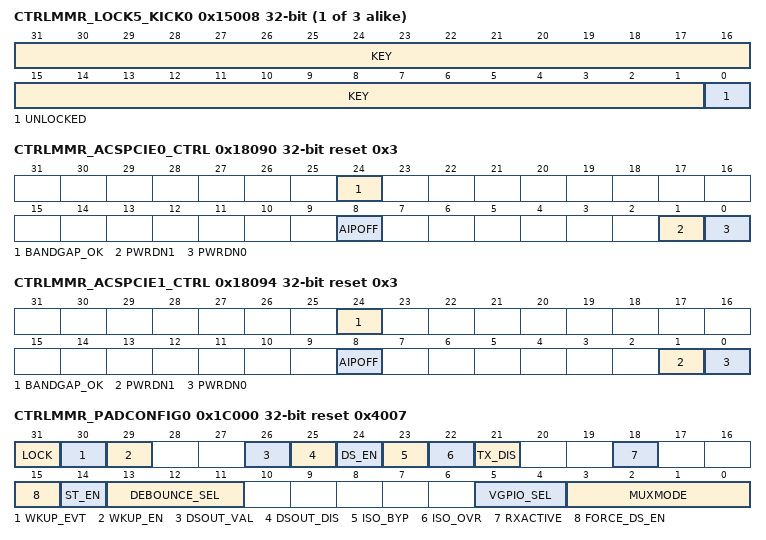
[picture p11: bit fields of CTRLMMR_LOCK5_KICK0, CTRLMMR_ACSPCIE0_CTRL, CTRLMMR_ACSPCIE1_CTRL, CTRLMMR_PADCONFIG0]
{0x1008+0x4000*i} CTRLMMR_LOCK{i}_KICK0 (i=5..7) — Lower 32-bits of Partition{i} write lock key. This register must be written with the designated key value followed by a write to with its key value before write-protected Partition {i} registers can be written.
  [31:1] KEY rw — Write the kick0 unlock value followed by the kick1 unlock value to unlock the write-protected Partition{i} registers
  [0] UNLOCKED ro — Unlock status. When set indicates that the proper unlock sequence has been performed and the partition is unlocked for writing.
{0x100C+0x4000*i} CTRLMMR_LOCK{i}_KICK1 rw (i=5..7) — Upper 32-bits of Partition {i} write lock key. This register must be written with the designated key value after a write to with its key value before write-protected Partition {i} registers can be written.
  [31:0] KEY — Write the kick1 unlock value after the kick0 unlock value to unlock the write-protected Partition{i} registers
0x18090 CTRLMMR_ACSPCIE0_CTRL reset 0x3 (reset mask 0xFEFFFFFF) — Controls the ACSPCIE0 module.
  [24] BANDGAP_OK ro — Bandgap output okay
  [8] AIPOFF rw — Testmode enable
  [1] PWRDN1 rw — Disable (tristate) PAD1 IO buffers
  [0] PWRDN0 rw — Disable (tristate) PAD0 IO buffers
0x18094 CTRLMMR_ACSPCIE1_CTRL reset 0x3 (reset mask 0xFEFFFFFF) — Controls the ACSPCIE1 module.
  [24] BANDGAP_OK ro — Bandgap output okay when set
  [8] AIPOFF rw — Testmode enable when set
  [1] PWRDN1 rw — Disable (tristate) PAD1 IO buffers when set
  [0] PWRDN0 rw — Disable (tristate) PAD0 IO buffers when set
0x1C000 CTRLMMR_PADCONFIG0 reset 0x4007 — Register to control pin configuration and muxing.
  [31] LOCK rw
  [30] WKUP_EVT ro — Wakeup event status
  [29] WKUP_EN rw — Wakeup enable
  [26] DSOUT_VAL rw — Deep Sleep output value
  [25] DSOUT_DIS rw — Deep Sleep output disable
  [24] DS_EN rw — Deep Sleep override control
  [23] ISO_BYP rw — Isolation Bypass
  [22] ISO_OVR rw — Isolation Override
  [21] TX_DIS rw — Driver Disable
  [18] RXACTIVE rw — Input enable for the Pad
  [15] FORCE_DS_EN rw — Enable pad Deep Sleep controls by overriding DMSC gating
  [14] ST_EN rw — Receiver Schmitt Trigger enable
  [13:11] DEBOUNCE_SEL rw — Selects the debouce period for the pad.
  [5:4] VGPIO_SEL rw — Virtual MAIN_GPIO instance select. 0h - Implement GPIO in GPIO_0/1 instance 1h - Implement GPIO in GPIO_2/3 instance 2h - Implement GPIO in GPIO_4/5 instance 3h - Implement GPIO in GPIO_6/7 instance
  [3:0] MUXMODE rw — Pad functional signal mux selection 0h - Mux Mode 0 1h - Mux Mode 1 2h - Mux Mode 2 3h - Mux Mode 3 4h - Mux Mode 4 5h - Mux Mode 5 6h - Mux Mode 6 7h - Mux Mode 7 8h - Mux Mode 8 9h - Mux Mode 9 Ah - Mux Mode 10 Bh - Mux Mode 11 Ch - Mux Mode 12 Dh - Mux Mode 13 Eh - Mux Mode 14 Fh - Mux Mode 15
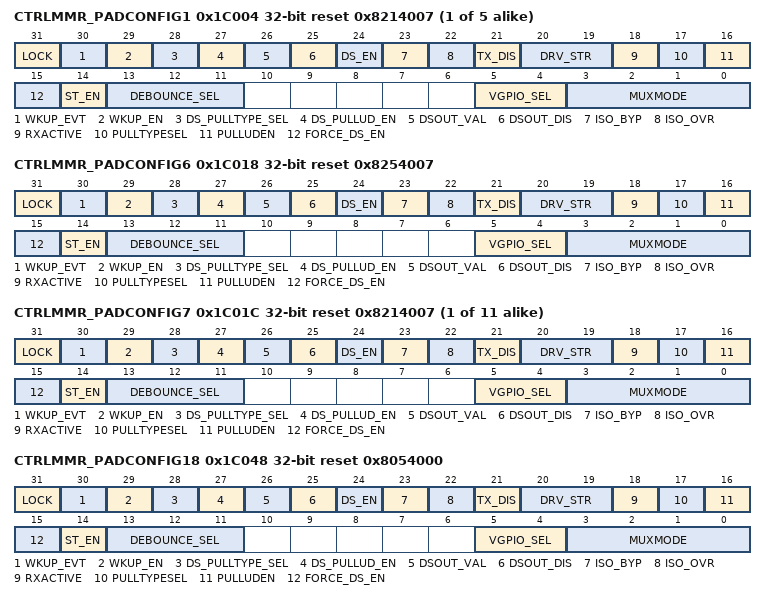
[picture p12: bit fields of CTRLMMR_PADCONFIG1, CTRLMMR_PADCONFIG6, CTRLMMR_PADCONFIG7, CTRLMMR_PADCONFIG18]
{0x1C000+4i} CTRLMMR_PADCONFIG{i} reset 0x8214007 (i=1..5) — Register to control pin configuration and muxing.
  [31] LOCK rw
  [30] WKUP_EVT ro — Wakeup event status
  [29] WKUP_EN rw — Wakeup enable
  [28] DS_PULLTYPE_SEL rw — Deep Sleep pull-up/down selection
  [27] DS_PULLUD_EN rw — Deep Sleep pull-up/down enable (active low)
  [26] DSOUT_VAL rw — Deep Sleep output value
  [25] DSOUT_DIS rw — Deep Sleep output disable
  [24] DS_EN rw — Deep Sleep override control
  [23] ISO_BYP rw — Isolation Bypass
  [22] ISO_OVR rw — Isolation Override
  [21] TX_DIS rw — Driver Disable
  [20:19] DRV_STR rw — Drive Strength Control . Selects the drive strength value for LVCMOS pins. (Does not apply to other pin types)
  [18] RXACTIVE rw — Input enable for the Pad
  [17] PULLTYPESEL rw — Pad Pullup / Pulldown type selection
  [16] PULLUDEN rw — Pad Pullup / Pulldown enable. This is an active low signal.
  [15] FORCE_DS_EN rw — Enable pad Deep Sleep controls by overriding DMSC gating
  [14] ST_EN rw — Receiver Schmitt Trigger enable
  [13:11] DEBOUNCE_SEL rw — Selects the debouce period for the pad.
  [5:4] VGPIO_SEL rw — Virtual MAIN_GPIO instance select. 0h - Implement GPIO in GPIO_0/1 instance 1h - Implement GPIO in GPIO_2/3 instance 2h - Implement GPIO in GPIO_4/5 instance 3h - Implement GPIO in GPIO_6/7 instance
  [3:0] MUXMODE rw — Pad functional signal mux selection 0h - Mux Mode 0 1h - Mux Mode 1 2h - Mux Mode 2 3h - Mux Mode 3 4h - Mux Mode 4 5h - Mux Mode 5 6h - Mux Mode 6 7h - Mux Mode 7 8h - Mux Mode 8 9h - Mux Mode 9 Ah - Mux Mode 10 Bh - Mux Mode 11 Ch - Mux Mode 12 Dh - Mux Mode 13 Eh - Mux Mode 14 Fh - Mux Mode 15
0x1C018 CTRLMMR_PADCONFIG6 reset 0x8254007 — Register to control pin configuration and muxing.
  fields as CTRLMMR_PADCONFIG1
{0x1C000+4i} CTRLMMR_PADCONFIG{i} reset 0x8214007 (i=7..17) — Register to control pin configuration and muxing.
  fields as CTRLMMR_PADCONFIG1
0x1C048 CTRLMMR_PADCONFIG18 reset 0x8054000 — Register to control pin configuration and muxing.
  fields as CTRLMMR_PADCONFIG1
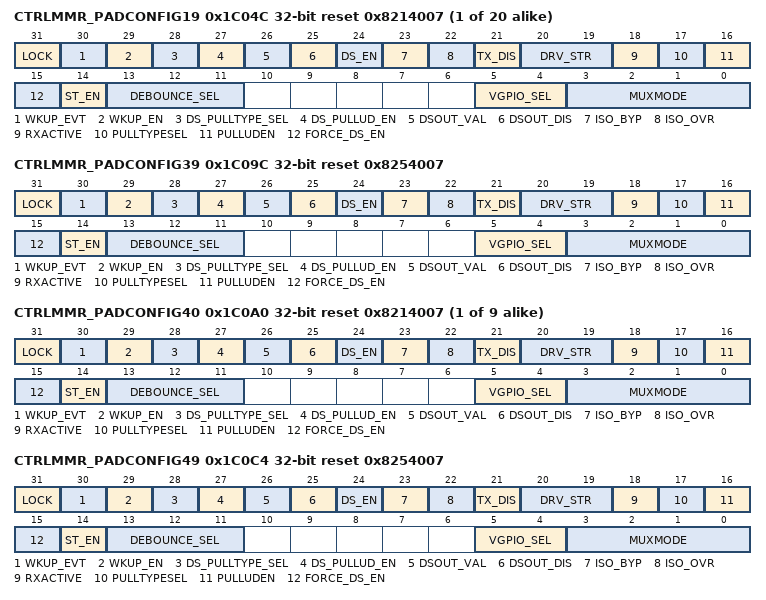
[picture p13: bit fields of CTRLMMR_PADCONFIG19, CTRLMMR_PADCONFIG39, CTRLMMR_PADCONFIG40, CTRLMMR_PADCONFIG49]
{0x1C000+4i} CTRLMMR_PADCONFIG{i} reset 0x8214007 (i=19..38) — Register to control pin configuration and muxing.
  fields as CTRLMMR_PADCONFIG1
0x1C09C CTRLMMR_PADCONFIG39 reset 0x8254007 — Register to control pin configuration and muxing.
  fields as CTRLMMR_PADCONFIG1
{0x1C000+4i} CTRLMMR_PADCONFIG{i} reset 0x8214007 (i=40..48) — Register to control pin configuration and muxing.
  fields as CTRLMMR_PADCONFIG1
0x1C0C4 CTRLMMR_PADCONFIG49 reset 0x8254007 — Register to control pin configuration and muxing.
  fields as CTRLMMR_PADCONFIG1
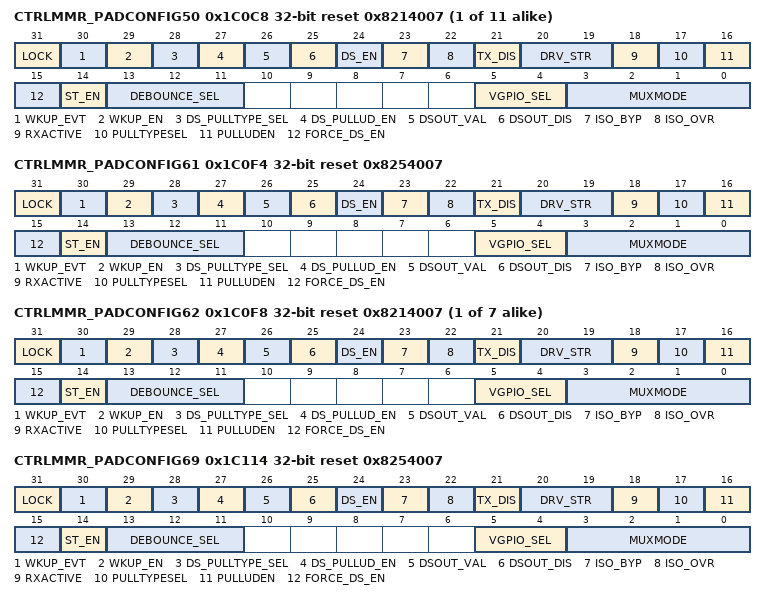
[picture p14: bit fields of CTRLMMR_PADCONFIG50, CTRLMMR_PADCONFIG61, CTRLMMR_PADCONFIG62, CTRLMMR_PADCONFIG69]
{0x1C000+4i} CTRLMMR_PADCONFIG{i} reset 0x8214007 (i=50..60) — Register to control pin configuration and muxing.
  fields as CTRLMMR_PADCONFIG1
0x1C0F4 CTRLMMR_PADCONFIG61 reset 0x8254007 — Register to control pin configuration and muxing.
  fields as CTRLMMR_PADCONFIG1
{0x1C000+4i} CTRLMMR_PADCONFIG{i} reset 0x8214007 (i=62..68) — Register to control pin configuration and muxing.
  fields as CTRLMMR_PADCONFIG1
0x1C114 CTRLMMR_PADCONFIG69 reset 0x8254007 — Register to control pin configuration and muxing.
  fields as CTRLMMR_PADCONFIG1
{0x1C000+4i} CTRLMMR_PADCONFIG{i} reset 0x8214007 (i=70..80) — Register to control pin configuration and muxing.
  fields as CTRLMMR_PADCONFIG1
0x1C144 CTRLMMR_PADCONFIG81 reset 0x8254007 — Register to control pin configuration and muxing.
  fields as CTRLMMR_PADCONFIG1
{0x1C000+4i} CTRLMMR_PADCONFIG{i} reset 0x8214007 (i=82..135) — Register to control pin configuration and muxing.
  fields as CTRLMMR_PADCONFIG1
{0x1C000+4i} CTRLMMR_PADCONFIG{i} reset 0x44007 (i=136..139) — Register to control pin configuration and muxing.
  fields as CTRLMMR_PADCONFIG0
0x1C230 CTRLMMR_PADCONFIG140 reset 0x8214007 — Register to control pin configuration and muxing.
  fields as CTRLMMR_PADCONFIG1
0x1C234 CTRLMMR_PADCONFIG141 reset 0x8214007 — Register to control pin configuration and muxing.
  fields as CTRLMMR_PADCONFIG1
0x1C238 CTRLMMR_PADCONFIG142 reset 0x8254007 — Register to control pin configuration and muxing.
  fields as CTRLMMR_PADCONFIG1
0x1C23C CTRLMMR_PADCONFIG143 reset 0x8254007 — Register to control pin configuration and muxing.
  fields as CTRLMMR_PADCONFIG1
{0x1C000+4i} CTRLMMR_PADCONFIG{i} reset 0x8214007 (i=144..149) — Register to control pin configuration and muxing.
  [31] LOCK rw
  [30] WKUP_EVT ro — Wakeup event status
  [29] WKUP_EN rw — Wakeup enable
  [28] DS_PULLTYPE_SEL rw — Deep Sleep pull-up/down selection
  [27] DS_PULLUD_EN rw — Deep Sleep pull-up/down enable (active low)
  [26] DSOUT_VAL rw — Deep Sleep output value
  [25] DSOUT_DIS rw — Deep Sleep output disable
  [24] DS_EN rw — Deep Sleep override control
  [23] ISO_BYP rw — Isolation Bypass
  [22] ISO_OVR rw — Isolation Override
  [21] TX_DIS rw — Driver Disable
  [18] RXACTIVE rw — Input enable for the Pad
  [17] PULLTYPESEL rw — Pad Pullup / Pulldown type selection
  [16] PULLUDEN rw — Pad Pullup / Pulldown enable. This is an active low signal.
  [15] FORCE_DS_EN rw — Enable pad Deep Sleep controls by overriding DMSC gating
  [14] ST_EN rw — Receiver Schmitt Trigger enable
  [13:11] DEBOUNCE_SEL rw — Selects the debouce period for the pad.
  [5:4] VGPIO_SEL rw — Virtual MAIN_GPIO instance select. 0h - Implement GPIO in GPIO_0/1 instance 1h - Implement GPIO in GPIO_2/3 instance 2h - Implement GPIO in GPIO_4/5 instance 3h - Implement GPIO in GPIO_6/7 instance
  [3:0] MUXMODE rw — Pad functional signal mux selection 0h - Mux Mode 0 1h - Mux Mode 1 2h - Mux Mode 2 3h - Mux Mode 3 4h - Mux Mode 4 5h - Mux Mode 5 6h - Mux Mode 6 7h - Mux Mode 7 8h - Mux Mode 8 9h - Mux Mode 9 Ah - Mux Mode 10 Bh - Mux Mode 11 Ch - Mux Mode 12 Dh - Mux Mode 13 Eh - Mux Mode 14 Fh - Mux Mode 15
0x1C258 CTRLMMR_PADCONFIG150 reset 0x8214007 — Register to control pin configuration and muxing.
  fields as CTRLMMR_PADCONFIG1
0x1C25C CTRLMMR_PADCONFIG151 reset 0x8214007 — Register to control pin configuration and muxing.
  fields as CTRLMMR_PADCONFIG1
{0x1C000+4i} CTRLMMR_PADCONFIG{i} reset 0x8214007 (i=152..157) — Register to control pin configuration and muxing.
  fields as CTRLMMR_PADCONFIG144
0x1C278 CTRLMMR_PADCONFIG158 reset 0x8014000 — Register to control pin configuration and muxing.
  fields as CTRLMMR_PADCONFIG1
0x1C27C CTRLMMR_PADCONFIG159 reset 0x8014000 — Register to control pin configuration and muxing.
  fields as CTRLMMR_PADCONFIG1
0x1C280 CTRLMMR_PADCONFIG160 reset 0x44000 — Register to control pin configuration and muxing.
  fields as CTRLMMR_PADCONFIG1
0x1C284 CTRLMMR_PADCONFIG161 reset 0x10264000 — Register to control pin configuration and muxing.
  fields as CTRLMMR_PADCONFIG1
0x1C288 CTRLMMR_PADCONFIG162 reset 0x10024000 — Register to control pin configuration and muxing.
  fields as CTRLMMR_PADCONFIG1
0x1C28C CTRLMMR_PADCONFIG163 reset 0x10264000 — Register to control pin configuration and muxing.
  fields as CTRLMMR_PADCONFIG1
0x1C290 CTRLMMR_PADCONFIG164 reset 0x204007 — Register to control pin configuration and muxing.
  fields as CTRLMMR_PADCONFIG1
{0x1C000+4i} CTRLMMR_PADCONFIG{i} (i=165..170) — Register to control pin configuration and muxing.
  [31] LOCK rw
  [14] ST_EN rw — Receiver Schmitt Trigger enable
  [5:4] VGPIO_SEL rw — Virtual MAIN_GPIO instance select. 0h - Implement GPIO in GPIO_0/1 instance 1h - Implement GPIO in GPIO_2/3 instance 2h - Implement GPIO in GPIO_4/5 instance 3h - Implement GPIO in GPIO_6/7 instance
  [3:0] MUXMODE rw — Pad functional signal mux selection 0h - Mux Mode 0 1h - Mux Mode 1 2h - Mux Mode 2 3h - Mux Mode 3 4h - Mux Mode 4 5h - Mux Mode 5 6h - Mux Mode 6 7h - Mux Mode 7 8h - Mux Mode 8 9h - Mux Mode 9 Ah - Mux Mode 10 Bh - Mux Mode 11 Ch - Mux Mode 12 Dh - Mux Mode 13 Eh - Mux Mode 14 Fh - Mux Mode 15
0x1C2AC CTRLMMR_PADCONFIG171 reset 0x8214000 — Register to control pin configuration and muxing.
  fields as CTRLMMR_PADCONFIG144
0x1C2B0 CTRLMMR_PADCONFIG172 reset 0x8214000 — Register to control pin configuration and muxing.
  fields as CTRLMMR_PADCONFIG144
0xF00100 CTRLMMR_IPC_SET0 access not given — Generate interprocessor communication interrupt to C71x core0.
  [31:4] IPC_SRC_SET — Read returns current value (access W1TS)
  [0] IPC_SET — Read returns 0 (access W1TS)
